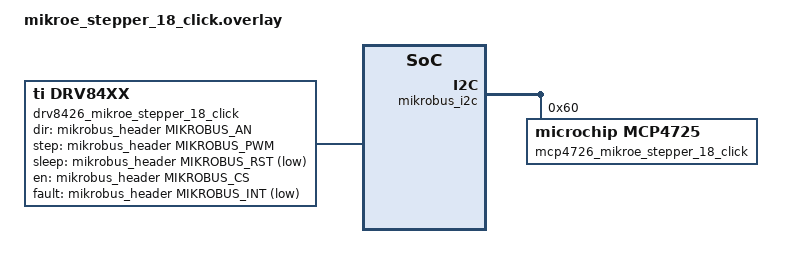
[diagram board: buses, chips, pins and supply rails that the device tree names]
/*
 * Copyright (c) 2025 Navimatix GmbH
 * SPDX-License-Identifier: Apache-2.0
 */

#include <zephyr/dt-bindings/gpio/mikro-bus.h>

/ {
	aliases {
		stepper = &drv8426_mikroe_stepper_18_click;
	};
};

&mikrobus_i2c {
	status = "okay";

	mcp4726_mikroe_stepper_18_click: mcp4726@70 {
		status = "okay";
		compatible = "microchip,mcp4725";
		reg = <0x60>;

		#io-channel-cells = <1>;
	};
};

/ {
	drv8426_mikroe_stepper_18_click: drv8426 {
		status = "okay";
		compatible = "ti,drv84xx";

		dir-gpios = <&mikrobus_header MIKROBUS_AN 0>;
		step-gpios = <&mikrobus_header MIKROBUS_PWM 0>;
		sleep-gpios = <&mikrobus_header MIKROBUS_RST GPIO_ACTIVE_LOW>;
		en-gpios = <&mikrobus_header MIKROBUS_CS 0>;
		fault-gpios = <&mikrobus_header MIKROBUS_INT GPIO_ACTIVE_LOW>;
	};
};
